# BlueNRG1 register map
Vendor: STMicroelectronics; Series: BlueNRG1; File version: 2.0.0
CPU: CM0 r0p0, little endian, no MPU, no FPU, 2 interrupt priority bits
Registers are 32-bit, read-write, reset 0x0 unless marked. A register's access mark holds for its fields unless they carry their own. Offsets are from the block's base; [hi:lo] are bit positions; 'fields as' and 'values as' point back to an identical list.

## ADC
Base 0x40800000
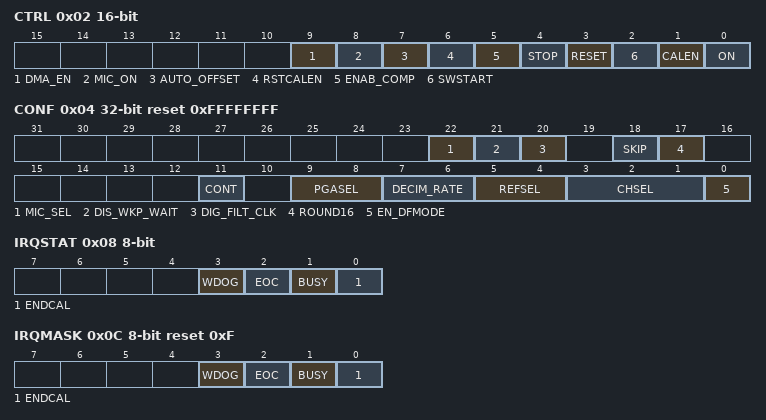
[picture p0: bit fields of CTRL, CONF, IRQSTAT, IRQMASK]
0x02 CTRL 16-bit — ADC control register
  [9] DMA_EN — Enables the DMA.<ul><li>0: DMA is disabled.</li><li>1: DMA is enabled.</li></ul>
    0=DMA_OFF (ADC DMA disable); 1=DMA_ON (ADC DMA enable)
  [8] MIC_ON — Enables the filter chain for voice when set to 1.<ul><li>0: Filter chain is disabled.</li><li>1: Filter chain is enabled.</li></ul>
    0=MIC_OFF (Filter chain disable); 1=MIC_ON (Filter chain enable)
  [7] AUTO_OFFSET — Enables the update of ADC_OFFSET register.<ul><li>0: ADC_OFFSET register is not updated.</li><li>1: ADC_OFFSET register is updated.</li></ul>
    0=CAL_OFF (ADC automatic calibration disable); 1=CAL_ON (ADC automatic calibration enable)
  [6] RSTCALEN — Disable the calibration phase when set to 1. This bit has to be set to disable the calibration each time calibration is enabled.
    1=RESET (Reset the ADCCALEN bit. Disable the automatic calibration when it is enabled)
  [5] ENAB_COMP — Enables the window comparator when set to 1. WDOG flag is ADC_SR register is set if the converted value is between ADCTHRESHOLD_HI and ADCTHRESHOLD_LO value.
  [4] STOP — Permits to stop the continuous conversion.<ul><li>0: continuous conversion is enabled but SWSTART and ADCON bits must be set.</li><li>1: stop the continuous conversion and switch off the ADC.</li></ul>
    1=STOP (Stop the continuous mode conversion)
  [3] RESET — Reset all the ADC APB registers when set.
    1=RESET (Reset all the registers content)
  [2] SWSTART — Starts the ADC conversion phase when set.
    1=START (Starts the ADC conversion phase when set.)
  [1] CALEN — Enables the calibration phase when set to 1. This bit is cleared and the calibration is disabled by setting the RSTADCCALEN bit.
    values as AUTO_OFFSET
  [0] ON — Starts ADC analog subsystem. This bit must be set before starting a conversion.<ul><li>0: ADC is OFF.</li><li>1: ADC is ON.</li></ul>
    0=OFF (ADC analog part disable); 1=ON (ADC analog part enable)
0x04 CONF reset 0xFFFFFFFF (reset mask 0xC) — ADC configuration register
  [22] MIC_SEL — Provides the clock on GPIO:<ul><li>0: Do not provided any external clock source.</li><li>1: Provide clock source from GPIO.</li></ul>
    0=DISABLE (Do not provided any external clock source); 1=ENABLE (Provide clock source from GPIO)
  [21] DIS_WKP_WAIT — Disable the wake-up timer before to start the conversion from input:<ul><li>0: Do not disable the wake up time before conversion.</li><li>1: Disable the wake up time before conversion.</li></ul>
    0=ENABLE (Do not disable the wake up time before conversion); 1=DISABLE (Disable the wake up time before conversion)
  [20] DIG_FILT_CLK — Frequency clock selection value on GPIO0 when MIC_SEL=1:<ul><li>0: 0.8 MHz.</li><li>1: 1.6 MHz.</li></ul>
    0=CLK_0MHz8 (Frequency clock to 0.8 MHz); 1=CLK_1MHz6 (Frequency clock to 1.6 MHz)
  [18] SKIP — It permits to bypass the filter comb to speed up the conversion for signal at low frequency:<ul><li>0: Filter for comb not bypassed.</li><li>1: Filter for comb bypassed.</li></ul>
    0=FILTER_OFF (Filter for comb not bypassed); 1=FILTER_ON (Filter for comb bypassed)
  [17] ROUND16 — Result mapped on 32 or 16 bits:<ul><li>0: Output result mapped to 32 bits.</li><li>1: Output result mapped to 16 bits.</li></ul>
    0=MAPPED_32 (Output result mapped to 32 bits); 1=MAPPED_16 (Output result mapped to 16 bits)
  [11] CONT — Enable the continuous conversion mode:<ul><li>0: Single conversion.</li><li>1: Continuous conversion.</li></ul>
    0=SINGLE (Single conversion mode); 1=CONT (Continuous conversion mode)
  [9:8] PGASEL — Set the input attenuator value:<ul><li>000b: Input attenuator at 0 dB.</li><li>001b: Input attenuator at 6.02 dB.</li><li>010b: Input attenuator at 9.54 dB.</li></ul>
    0=IN_ATT_0dB0 (Input attenuator at 0 dB); 1=IN_ATT_6dB02 (Input attenuator at 6.02 dB); 2=IN_ATT_9dB54 (Input attenuator at 9.54 dB)
  [7:6] DECIM_RATE — Set the ADC resolution:<ul><li>00b: Set the decimation factor to 200.</li><li>01b: Set the decimation factor to 100.</li><li>10b: Set the decimation factor to 64.</li><li>11b: Set the decimation factor to 32.</li></ul>
    0=DECIM_200 (Set the decimation factor to 200); 1=DECIM_100 (Set the decimation factor to 100); 2=DECIM_64 (Set the decimation factor to 64); 3=DECIM_32 (Set the decimation factor to 32)
  [5:4] REFSEL — Set the VREF for single ended conversion:<ul><li>00b: 0.0V.</li><li>01b: 0.4V.</li><li>10b: 0.6V.</li><li>11b: 1.2V.</li></ul>
    0=RESEL_0V0 (Set the VREF at 0.0 V); 1=RESEL_0V4 (Set the VREF at 0.4 V); 2=RESEL_0V6 (Set the VREF at 0.6 V); 3=RESEL_1V2 (Set the VREF at 1.2 V)
  [3:1] CHSEL — Select the input channel:<ul><li>000b: All switches open.</li><li>001b: Single ended through ADC2 pin. InP=VREF (internal), InN=ADC2 pin.</li><li>010b: Single ended through ADC1 pin. InP=ADC1 pin, InN=VREF (internal).</li><li>011b: Differential ADC1 pin - ADC2 pin, InP=ADC1 pin, InN=ADC2 pin.</li><li>101b: Battery level detector. InP=0.6V (internal), InN=BLD.</li><li>110b: Short InN=InP=0.6V (internal).</li></ul>
    0=ALL_SWITCH_OPEN; 1=SINGLE_VINP (Single ended InP=ANATEST2 pin, InN=VREF (internal)); 2=SINGLE_VINN (Single ended InN=ANATEST3 pin, InP=VREF (internal)); 3=DIFF_INP_INN (Differential InP=ANATEST2 pin, InN=ANATEST3 pin); 4=TEMP_SENS (InP=VTEMPSENS (internal), InN=0.6V (internal)); 5=BATT_SENS (InP=VBATSENS (internal), InN=0.6V (internal)); 6=SHORT (InP=InN=0.6V (internal))
  [0] EN_DFMODE — Control the current in differential mode:<ul><li>0: Differential mode with DC common mode current not nulled.</li><li>1: Differential mode with DC common mode current nulled.</li></ul>
    0=DFMODE_OFF (Differential mode with DC common mode current not nulled); 1=DFMODE_ON (Differential mode with DC common mode current nulled)
0x08 IRQSTAT 8-bit ro — IRQ masked status register
  [3] WDOG — 1: when the data is within the thresholds. Clear on register read.
  [2] EOC — 1: when the conversion is completed. Clear on register read.
  [1] BUSY — 1: during conversion. Clear on register read if BUSY condition no more active.
  [0] ENDCAL — 1: when the calibration is completed. Clear on register read.
0x0C IRQMASK 8-bit reset 0xF — It sets the mask for ADC interrupt
  [3] WDOG — Interrupt mask for the within the threhsold event:<ul><li>0: Interrupt is enabled.</li><li>1: Interrupt is disabled.</li></ul>
  [2] EOC — Interrupt mask for the end of conversion event:<ul><li>0: Interrupt is enabled.</li><li>1: Interrupt is disabled.</li></ul>
  [1] BUSY — Interrupt mask for the ADC busy event:<ul><li>0: Interrupt is enabled.</li><li>1: Interrupt is disabled.</li></ul>
  [0] ENDCAL — Interrupt mask for the end of calibration event:<ul><li>0: Interrupt is enabled.</li><li>1: Interrupt is disabled.</li></ul>
0x14 DATA_CONV ro — Result of the conversion in two complement format:<ul><li>if ROUND16=0: result is mapped on all 32-bit (can be truncated with loss of ADCDATAOUT[30:15])</li><li>if ROUND16=1: result is mapped on 16-bit (can be truncated with loss of ADCDATAOUT[15:0])</li></ul>
0x18 OFFSET — Offset for correction of converted data
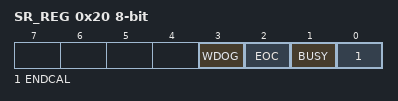
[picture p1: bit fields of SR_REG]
0x20 SR_REG 8-bit — ADC status register
  [3] WDOG — If ENAB_COMP=1, this bit indicates the result of the conversion is between high and low threshold:<ul><li>0: DATAOUT[31:0] is NOT between THRESHOLD_HI and THRESHOLD_LO values.</li><li>1: DATAOUT[31:0] is between THRESHOLD_HI and THRESHOLD_LO values.</li></ul>
  [2] EOC — 1: when the conversion is completed.
  [1] BUSY — 1: during conversion.
  [0] ENDCAL — 1: when the calibration is completed. The result of the calibration is written in the ADC_OFFSET register.
0x24 THRESHOLD_HI reset 0xFFFFFFFF — High threshold for window comparator
0x28 THRESHOLD_LO reset not defined — Low threshold for window comparator

## Notices in the file
License
